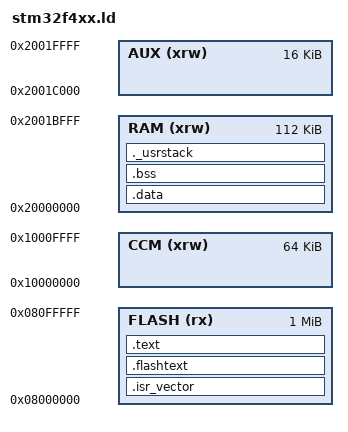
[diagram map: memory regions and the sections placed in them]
/*
Linker script for STM32F40x Chip Specific - sourcer32@gmail.com
*/


/* include the common STM32F40x sub-script */
INCLUDE "STM32F4_COMMON.ld"

/* Memory Spaces Definitions */
MEMORY
{
  RAM (xrw) : ORIGIN = 0x20000000, LENGTH = 112K
  AUX (xrw) : ORIGIN = 0x2001C000, LENGTH = 16K
  FLASH (rx) : ORIGIN = 0x8000000, LENGTH = 1M
  CCM (xrw) : ORIGIN = 0x10000000, LENGTH = 64K  /* also change _estack below */
}

/* highest address of the user mode stack */
_estack = 0x2001C000;

/* Sections Definitions */

SECTIONS
{
    /* for Cortex devices, the beginning of the startup code is stored in the .isr_vector section, which goes to FLASH */
    .isr_vector :
    {
	. = ALIGN(4);
        KEEP(*(.isr_vector))            /* Startup code */
	. = ALIGN(4);
    } >FLASH

    /* for some STRx devices, the beginning of the startup code is stored in the .flashtext section, which goes to FLASH */
    .flashtext :
    {
	. = ALIGN(4);
        *(.flashtext)            /* Startup code */
	. = ALIGN(4);
    } >FLASH


    /* the program code is stored in the .text section, which goes to Flash */
    .text :
    {
	    . = ALIGN(4);

        *(.text)                   /* remaining code */
        *(.text.*)                   /* remaining code */
        *(.rodata)                 /* read-only data (constants) */
        *(.rodata*)
        *(.glue_7)
        *(.glue_7t)

	    . = ALIGN(4);
   	 _etext = .;
	    /* This is used by the startup in order to initialize the .data secion */
   	 _sidata = _etext;
    } >FLASH



    /* This is the initialized data section
    The program executes knowing that the data is in the RAM
    but the loader puts the initial values in the FLASH (inidata).
    It is one task of the startup to copy the initial values from FLASH to RAM. */
    .data  : AT ( _sidata )
    {
	    . = ALIGN(4);
        /* This is used by the startup in order to initialize the .data secion */
        _sdata = . ;

        *(.data)
        *(.data.*)

	    . = ALIGN(4);
	    /* This is used by the startup in order to initialize the .data secion */
   	 _edata = . ;
    } >RAM



    /* This is the uninitialized data section */
    .bss :
    {
	    . = ALIGN(4);
        /* This is used by the startup in order to initialize the .bss secion */
        _sbss = .;

        *(.bss)
        *(.bss.*)
        *(COMMON)

	    . = ALIGN(4);
	    /* This is used by the startup in order to initialize the .bss secion */
   	 _ebss = . ;
    } >RAM

    PROVIDE ( end = _ebss );
    PROVIDE ( _end = _ebss );

    /* This is the user stack section
    This is just to check that there is enough RAM left for the User mode stack
    It should generate an error if it's full.
     */
    ._usrstack :
    {
	    . = ALIGN(4);
        _susrstack = . ;

        . = . + _Minimum_Stack_Size ;

	    . = ALIGN(4);
        _eusrstack = . ;
    } >RAM



    __exidx_start = .;
    __exidx_end = .;

    /* after that it's only debugging information. */

    /* remove the debugging information from the standard libraries */
    /DISCARD/ :
    {
     libc.a ( * )
     libm.a ( * )
     libgcc.a ( * )
     }

    /* Stabs debugging sections.  */
    .stab          0 : { *(.stab) }
    .stabstr       0 : { *(.stabstr) }
    .stab.excl     0 : { *(.stab.excl) }
    .stab.exclstr  0 : { *(.stab.exclstr) }
    .stab.index    0 : { *(.stab.index) }
    .stab.indexstr 0 : { *(.stab.indexstr) }
    .comment       0 : { *(.comment) }
    /* DWARF debug sections.
       Symbols in the DWARF debugging sections are relative to the beginning
       of the section so we begin them at 0.  */
    /* DWARF 1 */
    .debug          0 : { *(.debug) }
    .line           0 : { *(.line) }
    /* GNU DWARF 1 extensions */
    .debug_srcinfo  0 : { *(.debug_srcinfo) }
    .debug_sfnames  0 : { *(.debug_sfnames) }
    /* DWARF 1.1 and DWARF 2 */
    .debug_aranges  0 : { *(.debug_aranges) }
    .debug_pubnames 0 : { *(.debug_pubnames) }
    /* DWARF 2 */
    .debug_info     0 : { *(.debug_info .gnu.linkonce.wi.*) }
    .debug_abbrev   0 : { *(.debug_abbrev) }
    .debug_line     0 : { *(.debug_line) }
    .debug_frame    0 : { *(.debug_frame) }
    .debug_str      0 : { *(.debug_str) }
    .debug_loc      0 : { *(.debug_loc) }
    .debug_macinfo  0 : { *(.debug_macinfo) }
    /* SGI/MIPS DWARF 2 extensions */
    .debug_weaknames 0 : { *(.debug_weaknames) }
    .debug_funcnames 0 : { *(.debug_funcnames) }
    .debug_typenames 0 : { *(.debug_typenames) }
    .debug_varnames  0 : { *(.debug_varnames) }
}

